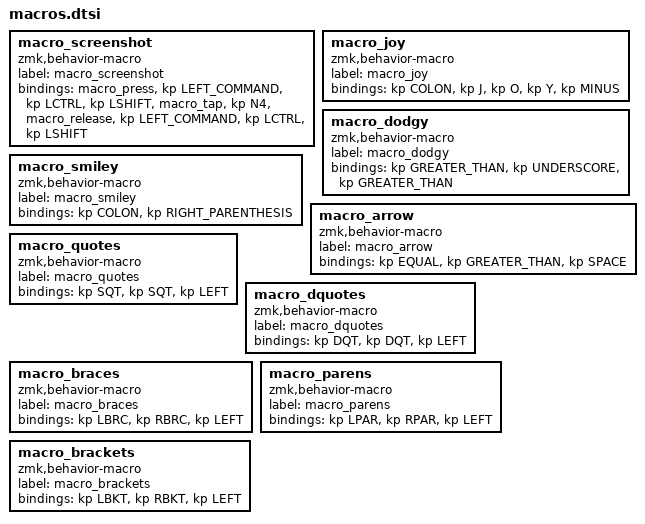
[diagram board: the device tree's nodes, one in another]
macro_screenshot: macro_screenshot{
compatible = "zmk,behavior-macro";
label = "macro_screenshot";
#binding-cells = <0>;
bindings = <&macro_press &kp LEFT_COMMAND &kp LCTRL &kp LSHIFT>, <&macro_tap &kp N4>, <&macro_release &kp LEFT_COMMAND &kp LCTRL &kp LSHIFT>;
};
macro_joy: macro_joy{
compatible = "zmk,behavior-macro";
label = "macro_joy";
#binding-cells = <0>;
bindings = <&kp COLON>, <&kp J>, <&kp O>, <&kp Y>, <&kp MINUS>;
};
macro_dodgy: macro_dodgy{
compatible = "zmk,behavior-macro";
label = "macro_dodgy";
#binding-cells = <0>;
bindings = <&kp GREATER_THAN>, <&kp UNDERSCORE>, <&kp GREATER_THAN>;
};
macro_smiley: macro_smiley{
compatible = "zmk,behavior-macro";
label = "macro_smiley";
#binding-cells = <0>;
bindings = <&kp COLON>, <&kp RIGHT_PARENTHESIS>;
};
macro_arrow: macro_arrow{
compatible = "zmk,behavior-macro";
label = "macro_arrow";
#binding-cells = <0>;
bindings = <&kp EQUAL>, <&kp GREATER_THAN>, <&kp SPACE>;
};
macro_quotes: macro_quotes{
compatible = "zmk,behavior-macro";
label = "macro_quotes";
#binding-cells = <0>;
bindings = <&kp SQT>, <&kp SQT>, <&kp LEFT>;
};
macro_dquotes: macro_dquotes{
compatible = "zmk,behavior-macro";
label = "macro_dquotes";
#binding-cells = <0>;
bindings = <&kp DQT>, <&kp DQT>, <&kp LEFT>;
};
macro_braces: macro_braces{
compatible = "zmk,behavior-macro";
label = "macro_braces";
#binding-cells = <0>;
bindings = <&kp LBRC>, <&kp RBRC>, <&kp LEFT>;
};
macro_parens: macro_parens{
compatible = "zmk,behavior-macro";
label = "macro_parens";
#binding-cells = <0>;
bindings = <&kp LPAR>, <&kp RPAR>, <&kp LEFT>;
};
macro_brackets: macro_brackets{
compatible = "zmk,behavior-macro";
label = "macro_brackets";
#binding-cells = <0>;
bindings = <&kp LBKT>, <&kp RBKT>, <&kp LEFT>;
};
